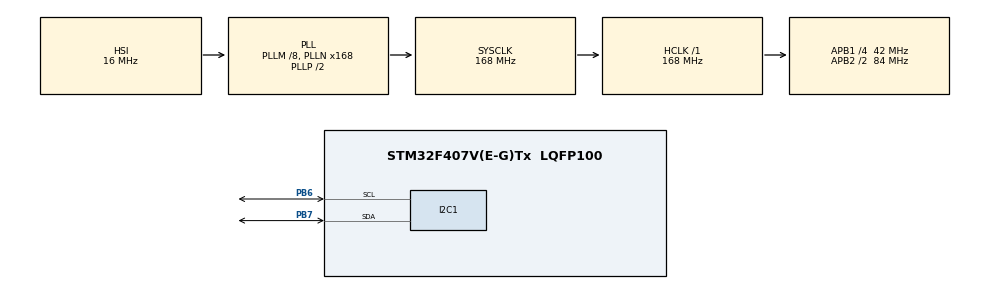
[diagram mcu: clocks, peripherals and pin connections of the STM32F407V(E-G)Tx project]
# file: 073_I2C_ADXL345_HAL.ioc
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I2C1.I2C_Mode=I2C_Fast
Mcu.Family=STM32F4
Mcu.Name=STM32F407V(E-G)Tx
Mcu.Package=LQFP100
NVIC.PriorityGroup=NVIC_PRIORITYGROUP_0
PB6.Mode=I2C
PB6.Signal=I2C1_SCL
PB7.Mode=I2C
PB7.Signal=I2C1_SDA
PH0-OSC_IN.Mode=HSE-External-Oscillator
PH0-OSC_IN.Signal=RCC_OSC_IN
PH1-OSC_OUT.Mode=HSE-External-Oscillator
PH1-OSC_OUT.Signal=RCC_OSC_OUT
ProjectManager.HeapSize=0x200
ProjectManager.StackSize=0x400
ProjectManager.TargetToolchain=STM32CubeIDE
RCC.48MHZClocksFreq_Value=48000000
RCC.AHBFreq_Value=168000000
RCC.APB1CLKDivider=RCC_HCLK_DIV4
RCC.APB1Freq_Value=42000000
RCC.APB1TimFreq_Value=84000000
RCC.APB2CLKDivider=RCC_HCLK_DIV2
RCC.APB2Freq_Value=84000000
RCC.APB2TimFreq_Value=168000000
RCC.CortexFreq_Value=168000000
RCC.HCLKFreq_Value=168000000
RCC.HSE_VALUE=8000000
RCC.HSI_VALUE=16000000
RCC.LSE_VALUE=32768
RCC.PLLM=8
RCC.PLLN=168
RCC.PLLQ=7
RCC.SYSCLKFreq_VALUE=168000000
RCC.SYSCLKSource=RCC_SYSCLKSOURCE_PLLCLK
RCC.VCOOutputFreq_Value=336000000
board=STM32F407G-DISC1

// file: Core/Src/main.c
/* USER CODE BEGIN Header */
/**
  ******************************************************************************
  * @file           : main.c
  * @brief          : Main program body
  ******************************************************************************
  * @attention
  *
  * Copyright (c) 2024 STMicroelectronics.
  * All rights reserved.
  *
  * This software is licensed under terms that can be found in the LICENSE file
  * in the root directory of this software component.
  * If no LICENSE file comes with this software, it is provided AS-IS.
  *
  ******************************************************************************
  */
/* USER CODE END Header */
#include "main.h"

I2C_HandleTypeDef hi2c1;

void SystemClock_Config(void);
static void MX_GPIO_Init(void);
static void MX_I2C1_Init(void);
/* USER CODE BEGIN PFP */

#define ADXL345_SLAVE_I2C_ADDRESS 0xa6

uint8_t myDatas[6];
int16_t X, Y, Z;
float xG, yG, zG;

void Scan_I2C_Address();

void ADXL345_Init();
void ADXL345_Read(uint8_t rRegister, uint8_t numberOfByte);
void ADXL345_Write(uint8_t wRegister, uint8_t value);

/* USER CODE END PFP */

/* USER CODE BEGIN 0 */
void Scan_I2C_Address()
{
	for(uint8_t i=0;i<=0xff;i++)
	{
		if(HAL_I2C_IsDeviceReady(&hi2c1, i, 1, 10) == HAL_OK)
			break;
	}
}

void ADXL345_Read(uint8_t rRegister, uint8_t numberOfByte)
{
	HAL_I2C_Mem_Read(&hi2c1, ADXL345_SLAVE_I2C_ADDRESS, rRegister, 1, myDatas, numberOfByte, 100);
}

void ADXL345_Write(uint8_t wRegister, uint8_t value)
{
	uint8_t datas[2] = {0};
	datas[0] = wRegister;
	datas[1] = value;

	HAL_I2C_Master_Transmit(&hi2c1, ADXL345_SLAVE_I2C_ADDRESS, datas, 2, 100);
}

void ADXL345_Init()
{
	//DEVID = Everything is ok.
	const uint8_t DEVID_OK  = 0xe5;
	const uint8_t DEVID_REG = 0x00;

	ADXL345_Read(DEVID_REG, 1); //Read register of DEVID_REG.

	if(myDatas[0] != DEVID_OK)  //If the read data is 0xe5, device is ready.
		return;

	ADXL345_Write(0x2d, 0x00);  //This reset the power bits.

	//Setup ->
	ADXL345_Write(0x2d, 0x08);  //Our settings. Measure bit is 1. Others are 0.

	ADXL345_Write(0x31, 0x01);  //Our range is +-4g.

}
/* USER CODE END 0 */

int main(void)
{

  /* MCU Configuration--------------------------------------------------------*/

  /* Reset of all peripherals, Initializes the Flash interface and the Systick. */
  HAL_Init();

  /* Configure the system clock */
  SystemClock_Config();

  /* Initialize all configured peripherals */
  MX_GPIO_Init();
  MX_I2C1_Init();
  /* USER CODE BEGIN 2 */

  Scan_I2C_Address();
  ADXL345_Init();

  /* USER CODE END 2 */

  /* Infinite loop */
  while (1)
  {

    /* USER CODE BEGIN 3 */
	  ADXL345_Read(0x32, 6); //-> It reads for 2 byte x, for 2 byte y, for 2 byte z. It reads a total of 6 bytes.

	  X = (myDatas[1] << 8) | myDatas[0];
	  Y = (myDatas[3] << 8) | myDatas[2];
	  Z = (myDatas[5] << 8) | myDatas[4];

	  xG = X * .0087;
	  yG = Y * .0087;
	  zG = Z * .0087;
  }
  /* USER CODE END 3 */
}

void SystemClock_Config(void)
{
  RCC_OscInitTypeDef RCC_OscInitStruct = {0};
  RCC_ClkInitTypeDef RCC_ClkInitStruct = {0};

  /** Configure the main internal regulator output voltage
  */
  __HAL_RCC_PWR_CLK_ENABLE();
  __HAL_PWR_VOLTAGESCALING_CONFIG(PWR_REGULATOR_VOLTAGE_SCALE1);

  /** Initializes the RCC Oscillators according to the specified parameters
  * in the RCC_OscInitTypeDef structure.
  */
  RCC_OscInitStruct.OscillatorType = RCC_OSCILLATORTYPE_HSI;
  RCC_OscInitStruct.HSIState = RCC_HSI_ON;
  RCC_OscInitStruct.HSICalibrationValue = RCC_HSICALIBRATION_DEFAULT;
  RCC_OscInitStruct.PLL.PLLState = RCC_PLL_ON;
  RCC_OscInitStruct.PLL.PLLSource = RCC_PLLSOURCE_HSI;
  RCC_OscInitStruct.PLL.PLLM = 8;
  RCC_OscInitStruct.PLL.PLLN = 168;
  RCC_OscInitStruct.PLL.PLLP = RCC_PLLP_DIV2;
  RCC_OscInitStruct.PLL.PLLQ = 7;
  if (HAL_RCC_OscConfig(&RCC_OscInitStruct) != HAL_OK)
  {
    Error_Handler();
  }

  /** Initializes the CPU, AHB and APB buses clocks
  */
  RCC_ClkInitStruct.ClockType = RCC_CLOCKTYPE_HCLK|RCC_CLOCKTYPE_SYSCLK
                              |RCC_CLOCKTYPE_PCLK1|RCC_CLOCKTYPE_PCLK2;
  RCC_ClkInitStruct.SYSCLKSource = RCC_SYSCLKSOURCE_PLLCLK;
  RCC_ClkInitStruct.AHBCLKDivider = RCC_SYSCLK_DIV1;
  RCC_ClkInitStruct.APB1CLKDivider = RCC_HCLK_DIV4;
  RCC_ClkInitStruct.APB2CLKDivider = RCC_HCLK_DIV2;

  if (HAL_RCC_ClockConfig(&RCC_ClkInitStruct, FLASH_LATENCY_5) != HAL_OK)
  {
    Error_Handler();
  }
}

static void MX_I2C1_Init(void)
{

  hi2c1.Instance = I2C1;
  hi2c1.Init.ClockSpeed = 400000;
  hi2c1.Init.DutyCycle = I2C_DUTYCYCLE_2;
  hi2c1.Init.OwnAddress1 = 0;
  hi2c1.Init.AddressingMode = I2C_ADDRESSINGMODE_7BIT;
  hi2c1.Init.DualAddressMode = I2C_DUALADDRESS_DISABLE;
  hi2c1.Init.OwnAddress2 = 0;
  hi2c1.Init.GeneralCallMode = I2C_GENERALCALL_DISABLE;
  hi2c1.Init.NoStretchMode = I2C_NOSTRETCH_DISABLE;
  if (HAL_I2C_Init(&hi2c1) != HAL_OK)
  {
    Error_Handler();
  }

}

static void MX_GPIO_Init(void)
{

  /* GPIO Ports Clock Enable */
  __HAL_RCC_GPIOH_CLK_ENABLE();
  __HAL_RCC_GPIOB_CLK_ENABLE();

}

void Error_Handler(void)
{
  __disable_irq();
  while (1)
  {
  }
}
